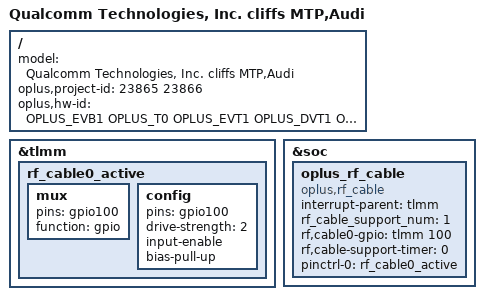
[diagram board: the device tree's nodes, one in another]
/dts-v1/;
/plugin/;
#include <dt-bindings/oplus/hw-id.h>
#include "../qcom/cliffs-mtp-overlay.dts"
#include "cliffs_overlay_common.dtsi"
#include "audi_overlay_common.dtsi"
#include "tp/audi-oplus-tp-23803.dtsi"
#include "nfc/audi-nfc-sn220.dtsi"
#include "oplus_misc/oplus-misc-23803.dtsi"
#include "oplus_chg/oplus-chg-23803.dtsi"
#include "oplus_chg/oplus-chg-23865-pps.dtsi"
#include "sensor/audi-sensor-23803.dtsi"
#include "oplus_fp/oplus_fp_23803.dtsi"

/ {
    model = "Qualcomm Technologies, Inc. cliffs MTP,Audi";

    oplus,project-id = <23865 23866>;
    oplus,hw-id = <OPLUS_EVB1 OPLUS_T0 OPLUS_EVT1 OPLUS_DVT1 OPLUS_PVT1>;
};

&tlmm {
  //#ifdef OPLUS_FEATURE_RF_CABLE_DETECT
  rf_cable0_active: rf_cable0_active {
    mux {
      pins = "gpio100";
      function = "gpio";
    };
    config {
      pins = "gpio100";
      drive-strength = <2>;
      input-enable;
      bias-pull-up;
    };
  };
  //#endif /* OPLUS_FEATURE_RF_CABLE_DETECT */
};

&soc {
  //#ifdef OPLUS_FEATURE_RF_CABLE_DETECT
  oplus_rf_cable {
    compatible = "oplus,rf_cable";
    interrupt-parent = <&tlmm>;
    rf_cable_support_num = <1>;
    rf,cable0-gpio = <&tlmm 100 0>;
    rf,cable-support-timer = <0>;
    pinctrl-names = "rf_cable_active";
    pinctrl-0 = <&rf_cable0_active>;
  };
  //#endif /* OPLUS_FEATURE_RF_CABLE_DETECT */
};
